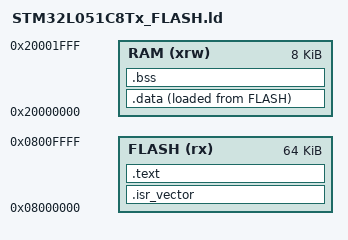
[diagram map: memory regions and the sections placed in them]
ENTRY(Reset_Handler)

MEMORY
{
    FLASH (rx) : ORIGIN = 0x08000000, LENGTH = 64K
    RAM (xrw)  : ORIGIN = 0x20000000, LENGTH = 8K
}

_estack = ORIGIN(RAM) + LENGTH(RAM);

SECTIONS
{
    .isr_vector :
    {
        KEEP(*(.isr_vector))
    } > FLASH

    .text :
    {
        . = ALIGN(4);
        *(.text)
        *(.text*)
        *(.rodata)
        *(.rodata*)
        . = ALIGN(4);
        _etext = .;
    } > FLASH

    .data :
    {
        . = ALIGN(4);
        _sdata = .;
        *(.data)
        *(.data*)
        . = ALIGN(4);
        _edata = .;
    } > RAM AT > FLASH

    _sidata = LOADADDR(.data);

    .bss :
    {
        . = ALIGN(4);
        _sbss = .;
        *(.bss)
        *(.bss*)
        *(COMMON)
        . = ALIGN(4);
        _ebss = .;
    } > RAM

    /DISCARD/ :
    {
        *(.ARM.exidx*)
        *(.ARM.extab*)
    }
}

ASSERT(_ebss + 0x400 <= ORIGIN(RAM) + LENGTH(RAM), "RAM collides with the 1KB stack")
